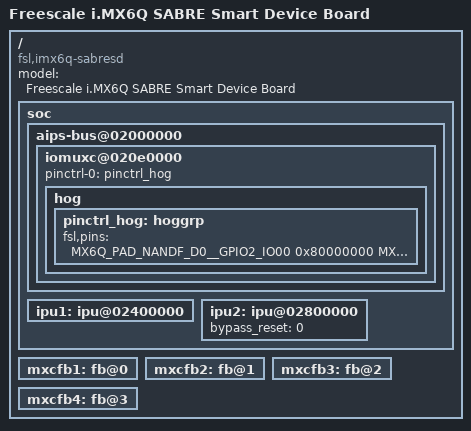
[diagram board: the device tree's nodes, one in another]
/*
 * Copyright 2012 Freescale Semiconductor, Inc.
 * Copyright 2011 Linaro Ltd.
 *
 * The code contained herein is licensed under the GNU General Public
 * License. You may obtain a copy of the GNU General Public License
 * Version 2 or later at the following locations:
 *
 * http://www.opensource.org/licenses/gpl-license.html
 * http://www.gnu.org/copyleft/gpl.html
 */

/dts-v1/;
#include "imx6q.dtsi"
#include "imx6qdl-sabresd.dtsi"

/ {
	model = "Freescale i.MX6Q SABRE Smart Device Board";
	compatible = "fsl,imx6q-sabresd", "fsl,imx6q";

	soc {
		aips-bus@02000000 { /* AIPS1 */
			iomuxc@020e0000 {
				pinctrl-names = "default";
				pinctrl-0 = <&pinctrl_hog>;

				hog {
					pinctrl_hog: hoggrp {
						fsl,pins = <
							MX6Q_PAD_NANDF_D0__GPIO2_IO00 0x80000000
							MX6Q_PAD_NANDF_D1__GPIO2_IO01 0x80000000
							MX6Q_PAD_NANDF_D2__GPIO2_IO02 0x80000000
							MX6Q_PAD_NANDF_D3__GPIO2_IO03 0x80000000
							MX6Q_PAD_NANDF_ALE__GPIO6_IO08 0x80000000
							MX6Q_PAD_NANDF_CLE__GPIO6_IO07 0x80000000
							MX6Q_PAD_EIM_D26__GPIO3_IO26 0x80000000
							MX6Q_PAD_EIM_CS1__GPIO2_IO24 0x80000000
							MX6Q_PAD_ENET_RXD0__GPIO1_IO27 0x80000000
							MX6Q_PAD_EIM_A25__GPIO5_IO02 0x80000000
							MX6Q_PAD_EIM_D23__GPIO3_IO23 0x80000000
							MX6Q_PAD_GPIO_1__WDOG2_B 0x80000000
							MX6Q_PAD_NANDF_RB0__GPIO6_IO10 0x80000000
							MX6Q_PAD_KEY_ROW1__GPIO4_IO09 0x80000000
							MX6Q_PAD_KEY_COL2__GPIO4_IO10 0x80000000
							MX6Q_PAD_SD3_RST__GPIO7_IO08 0x80000000
							MX6Q_PAD_GPIO_9__GPIO1_IO09 0x80000000
							MX6Q_PAD_SD1_DAT0__GPIO1_IO16 0x80000000
							MX6Q_PAD_SD1_DAT1__GPIO1_IO17 0x80000000
							MX6Q_PAD_SD1_DAT2__GPIO1_IO19 0x80000000
							MX6Q_PAD_SD1_CLK__GPIO1_IO20 0x80000000
							MX6Q_PAD_GPIO_0__CCM_CLKO1 0x130b0
							MX6Q_PAD_GPIO_4__GPIO1_IO04 0x80000000
							MX6Q_PAD_GPIO_5__GPIO1_IO05 0x80000000
							MX6Q_PAD_EIM_D29__GPIO3_IO29 0x80000000
						>;
					};
				};
			};
		};

		ipu1: ipu@02400000 { /* IPU1 */
			status = "okay";
		};

		ipu2: ipu@02800000 { /* IPU2 */
			bypass_reset = <0>;
			status = "okay";
		};
	};

	mxcfb1: fb@0 {
		status = "okay";
	};

	mxcfb2: fb@1 {
		status = "okay";
	};

	mxcfb3: fb@2 {
		status = "okay";
	};

	mxcfb4: fb@3 {
		status = "okay";
	};
};
